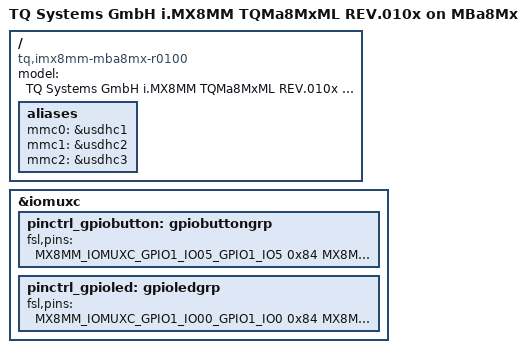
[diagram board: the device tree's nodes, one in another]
// SPDX-License-Identifier: GPL-2.0+
/*
 * Copyright 2021 TQ-Systems GmbH
 */

/dts-v1/;

#include "fsl-imx8mm-tqma8mxml-r0100.dtsi"
#include "fsl-imx8mm-mba8mx.dtsi"

/delete-node/ &pinctrl_gpiobutton;
/delete-node/ &pinctrl_gpioled;

/ {
	model = "TQ Systems GmbH i.MX8MM TQMa8MxML REV.010x on MBa8Mx";
	compatible = "tq,imx8mm-mba8mx-r0100", "tq,imx8mm-tqma8mxml-r0100", "fsl,imx8mm";

	aliases {
		mmc0 = &usdhc1;
		mmc1 = &usdhc2;
		mmc2 = &usdhc3;
	};
};

&iomuxc {
	pinctrl_gpiobutton: gpiobuttongrp {
		fsl,pins = <
			MX8MM_IOMUXC_GPIO1_IO05_GPIO1_IO5	0x84
			MX8MM_IOMUXC_GPIO1_IO07_GPIO1_IO7	0x84
			MX8MM_IOMUXC_NAND_WE_B_GPIO3_IO17	0x84
		>;
	};

	pinctrl_gpioled: gpioledgrp {
		fsl,pins = <
			MX8MM_IOMUXC_GPIO1_IO00_GPIO1_IO0	0x84
			MX8MM_IOMUXC_GPIO1_IO08_GPIO1_IO8	0x84
			MX8MM_IOMUXC_NAND_READY_B_GPIO3_IO16	0x84
		>;
	};
};
